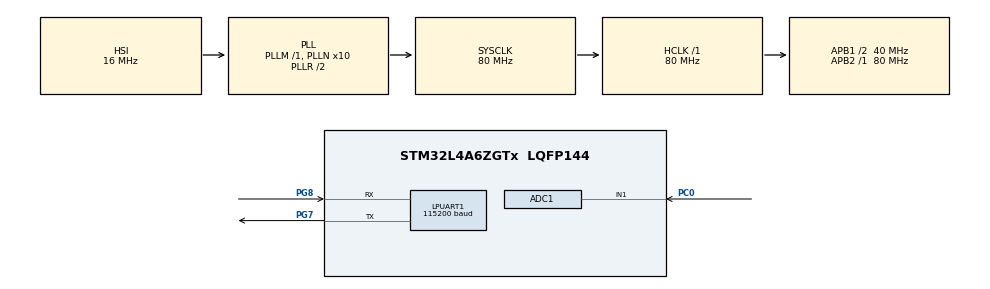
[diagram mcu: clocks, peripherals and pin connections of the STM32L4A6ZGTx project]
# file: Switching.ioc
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ADC1.Channel-0\#ChannelRegularConversion=ADC_CHANNEL_1
ADC1.ContinuousConvMode=ENABLE
ADC1.NbrOfConversion=1
ADC1.NbrOfConversionFlag=1
ADC1.OffsetNumber-0\#ChannelRegularConversion=ADC_OFFSET_NONE
ADC1.Rank-0\#ChannelRegularConversion=1
ADC1.SamplingTime-0\#ChannelRegularConversion=ADC_SAMPLETIME_2CYCLES_5
ADC1.master=1
Dma.ADC1.0.Direction=DMA_PERIPH_TO_MEMORY
Dma.ADC1.0.Instance=DMA1_Channel1
Dma.ADC1.0.MemDataAlignment=DMA_MDATAALIGN_HALFWORD
Dma.ADC1.0.MemInc=DMA_MINC_ENABLE
Dma.ADC1.0.Mode=DMA_NORMAL
Dma.ADC1.0.PeriphDataAlignment=DMA_PDATAALIGN_HALFWORD
Dma.ADC1.0.PeriphInc=DMA_PINC_DISABLE
Dma.ADC1.0.Priority=DMA_PRIORITY_LOW
Dma.Request0=ADC1
LPUART1.BaudRate=115200
LPUART1.WordLength=UART_WORDLENGTH_8B
Mcu.Family=STM32L4
Mcu.Name=STM32L4A6ZGTx
Mcu.Package=LQFP144
NVIC.DMA1_Channel1_IRQn=true\:0\:0\:false\:false\:true\:false\:true\:true
NVIC.PriorityGroup=NVIC_PRIORITYGROUP_4
PC0.Signal=ADCx_IN1
PG7.Mode=Asynchronous
PG7.Signal=LPUART1_TX
PG8.Mode=Asynchronous
PG8.Signal=LPUART1_RX
ProjectManager.HeapSize=0x200
ProjectManager.StackSize=0x400
ProjectManager.TargetToolchain=STM32CubeIDE
RCC.ADCFreq_Value=64000000
RCC.AHBFreq_Value=80000000
RCC.APB1CLKDivider=RCC_HCLK_DIV2
RCC.APB1Freq_Value=40000000
RCC.APB1TimFreq_Value=80000000
RCC.APB2Freq_Value=80000000
RCC.APB2TimFreq_Value=80000000
RCC.CortexFreq_Value=80000000
RCC.FLatency=FLASH_LATENCY_4
RCC.HCLKFreq_Value=80000000
RCC.HSE_VALUE=8000000
RCC.HSI48_VALUE=48000000
RCC.HSI_VALUE=16000000
RCC.MSI_VALUE=4000000
RCC.PLLN=10
RCC.PLLSourceVirtual=RCC_PLLSOURCE_HSI
RCC.SYSCLKFreq_VALUE=80000000
RCC.SYSCLKSource=RCC_SYSCLKSOURCE_PLLCLK
RCC.USBFreq_Value=64000000
RCC.VCOOutputFreq_Value=160000000
SH.ADCx_IN1.0=ADC1_IN1,IN1-Single-Ended
board=NUCLEO-L4A6ZG

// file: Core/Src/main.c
/* USER CODE BEGIN Header */
/**
  ******************************************************************************
  * @file           : main.c
  * @brief          : Main program body
  ******************************************************************************
  * @attention
  *
  * Copyright (c) 2024 STMicroelectronics.
  * All rights reserved.
  *
  * This software is licensed under terms that can be found in the LICENSE file
  * in the root directory of this software component.
  * If no LICENSE file comes with this software, it is provided AS-IS.
  *
  ******************************************************************************
  */
/* USER CODE END Header */
#include "main.h"
#include "adc.h"
#include "switch.h"

/* USER CODE BEGIN Includes */
#include <stdio.h>
#include <string.h>
/* USER CODE END Includes */

UART_HandleTypeDef hlpuart1;

/* USER CODE BEGIN PV */
char msg[100];
extern uint8_t convCompleted;

/* USER CODE END PV */

void SystemClock_Config(void);
static void MX_GPIO_Init(void);
 void MX_DMA_Init(void);
static void MX_LPUART1_UART_Init(void);
// main.c
/* USER CODE BEGIN PV */
extern uint8_t convCompleted;  // Declare the variable here
/* USER CODE END PV */

int main(void)
{

  /* MCU Configuration--------------------------------------------------------*/

  /* Reset of all peripherals, Initializes the Flash interface and the Systick. */
  HAL_Init();

  /* Configure the system clock */
  SystemClock_Config();

  /* Initialize all configured peripherals */
  MX_GPIO_Init();
  MX_DMA_Init();
  MX_LPUART1_UART_Init();
  MX_ADC1_Init();

  /* USER CODE BEGIN 2 */
  HAL_ADC_Start_DMA(&hadc1, (uint32_t *)raw, NUM_SAMPLES);
  /* USER CODE END 2 */

  /* Infinite loop */
  while (1)
  {

    /* USER CODE BEGIN 3 */
    if (convCompleted)
    {
        potSum = 0;

        for (uint16_t i = 0; i < NUM_SAMPLES; i++)
        {
            potSum += raw[i];
            controlLED(raw[i]);  // Call function from switch.c
        }

        calculate_and_print_average();

        convCompleted = 0;

        HAL_ADC_Start_DMA(&hadc1, (uint32_t *)raw, NUM_SAMPLES);
    }

    HAL_Delay(1000);
  }
  /* USER CODE END 3 */
}

void SystemClock_Config(void)
{
  RCC_OscInitTypeDef RCC_OscInitStruct = {0};
  RCC_ClkInitTypeDef RCC_ClkInitStruct = {0};

  /** Configure the main internal regulator output voltage
  */
  if (HAL_PWREx_ControlVoltageScaling(PWR_REGULATOR_VOLTAGE_SCALE1) != HAL_OK)
  {
    Error_Handler();
  }

  /** Initializes the RCC Oscillators according to the specified parameters
  * in the RCC_OscInitTypeDef structure.
  */
  RCC_OscInitStruct.OscillatorType = RCC_OSCILLATORTYPE_HSI;
  RCC_OscInitStruct.HSIState = RCC_HSI_ON;
  RCC_OscInitStruct.HSICalibrationValue = RCC_HSICALIBRATION_DEFAULT;
  RCC_OscInitStruct.PLL.PLLState = RCC_PLL_ON;
  RCC_OscInitStruct.PLL.PLLSource = RCC_PLLSOURCE_HSI;
  RCC_OscInitStruct.PLL.PLLM = 1;
  RCC_OscInitStruct.PLL.PLLN = 10;
  RCC_OscInitStruct.PLL.PLLP = RCC_PLLP_DIV2;
  RCC_OscInitStruct.PLL.PLLQ = RCC_PLLQ_DIV2;
  RCC_OscInitStruct.PLL.PLLR = RCC_PLLR_DIV2;
  if (HAL_RCC_OscConfig(&RCC_OscInitStruct) != HAL_OK)
  {
    Error_Handler();
  }

  /** Initializes the CPU, AHB and APB buses clocks
  */
  RCC_ClkInitStruct.ClockType = RCC_CLOCKTYPE_HCLK|RCC_CLOCKTYPE_SYSCLK
                              |RCC_CLOCKTYPE_PCLK1|RCC_CLOCKTYPE_PCLK2;
  RCC_ClkInitStruct.SYSCLKSource = RCC_SYSCLKSOURCE_PLLCLK;
  RCC_ClkInitStruct.AHBCLKDivider = RCC_SYSCLK_DIV1;
  RCC_ClkInitStruct.APB1CLKDivider = RCC_HCLK_DIV2;
  RCC_ClkInitStruct.APB2CLKDivider = RCC_HCLK_DIV1;

  if (HAL_RCC_ClockConfig(&RCC_ClkInitStruct, FLASH_LATENCY_4) != HAL_OK)
  {
    Error_Handler();
  }
}

static void MX_LPUART1_UART_Init(void)
{

  hlpuart1.Instance = LPUART1;
  hlpuart1.Init.BaudRate = 115200;
  hlpuart1.Init.WordLength = UART_WORDLENGTH_8B;
  hlpuart1.Init.StopBits = UART_STOPBITS_1;
  hlpuart1.Init.Parity = UART_PARITY_NONE;
  hlpuart1.Init.Mode = UART_MODE_TX_RX;
  hlpuart1.Init.HwFlowCtl = UART_HWCONTROL_NONE;
  hlpuart1.Init.OneBitSampling = UART_ONE_BIT_SAMPLE_DISABLE;
  hlpuart1.AdvancedInit.AdvFeatureInit = UART_ADVFEATURE_NO_INIT;
  if (HAL_UART_Init(&hlpuart1) != HAL_OK)
  {
    Error_Handler();
  }

}

static void MX_GPIO_Init(void)
{

  /* GPIO Ports Clock Enable */
  __HAL_RCC_GPIOC_CLK_ENABLE();
  __HAL_RCC_GPIOG_CLK_ENABLE();
  HAL_PWREx_EnableVddIO2();

}

void Error_Handler(void)
{
  __disable_irq();
  while (1)
  {
  }
}
